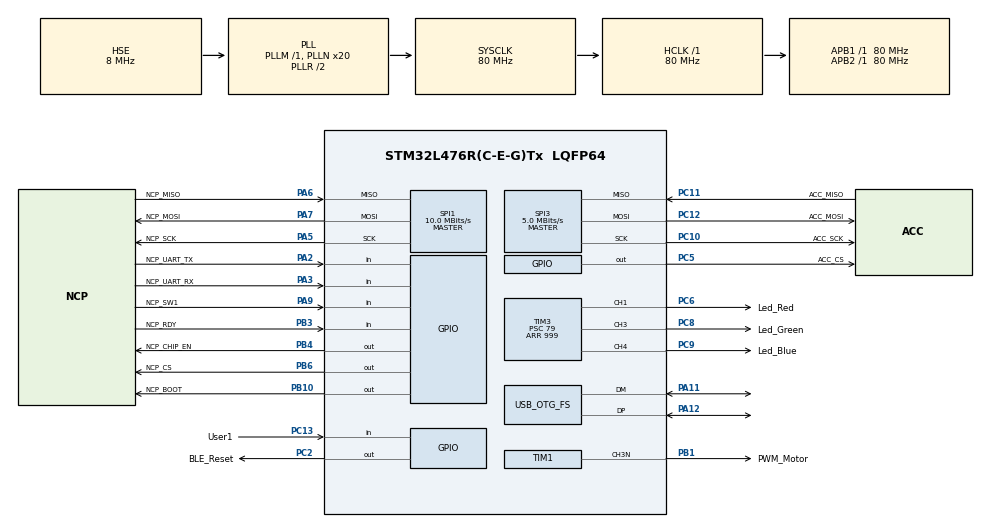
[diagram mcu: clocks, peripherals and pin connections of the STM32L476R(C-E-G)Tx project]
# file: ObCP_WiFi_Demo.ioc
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ADC1.Channel-0\#ChannelRegularConversion=ADC_CHANNEL_TEMPSENSOR
ADC1.ClockPrescaler=ADC_CLOCK_ASYNC_DIV4
ADC1.NbrOfConversionFlag=1
ADC1.OffsetNumber-0\#ChannelRegularConversion=ADC_OFFSET_NONE
ADC1.Rank-0\#ChannelRegularConversion=1
ADC1.SamplingTime-0\#ChannelRegularConversion=ADC_SAMPLETIME_640CYCLES_5
ADC1.master=1
Mcu.Family=STM32L4
Mcu.Name=STM32L476R(C-E-G)Tx
Mcu.Package=LQFP64
NVIC.OTG_FS_IRQn=true\:2\:0\:false\:false\:true\:false\:true\:true
NVIC.PriorityGroup=NVIC_PRIORITYGROUP_4
PA11.Mode=Device_Only
PA11.Signal=USB_OTG_FS_DM
PA12.Mode=Device_Only
PA12.Signal=USB_OTG_FS_DP
PA13\ (JTMS-SWDIO).GPIO_Label=TMS
PA13\ (JTMS-SWDIO).Mode=Serial_Wire
PA13\ (JTMS-SWDIO).Signal=SYS_JTMS-SWDIO
PA14\ (JTCK-SWCLK).GPIO_Label=TCK
PA14\ (JTCK-SWCLK).Mode=Serial_Wire
PA14\ (JTCK-SWCLK).Signal=SYS_JTCK-SWCLK
PA2.GPIO_Label=NCP_UART_TX
PA2.GPIO_PuPd=GPIO_PULLUP
PA2.Signal=GPIO_Input
PA3.GPIO_Label=NCP_UART_RX
PA3.GPIO_PuPd=GPIO_PULLUP
PA3.Signal=GPIO_Input
PA5.GPIO_Label=NCP_SCK
PA5.GPIO_PuPd=GPIO_PULLDOWN
PA5.Mode=Full_Duplex_Master
PA5.Signal=SPI1_SCK
PA6.GPIO_Label=NCP_MISO
PA6.Mode=Full_Duplex_Master
PA6.Signal=SPI1_MISO
PA7.GPIO_Label=NCP_MOSI
PA7.GPIO_PuPd=GPIO_PULLDOWN
PA7.Mode=Full_Duplex_Master
PA7.Signal=SPI1_MOSI
PA9.GPIO_Label=NCP_SW1
PA9.GPIO_PuPd=GPIO_PULLUP
PA9.Signal=GPIO_Input
PB1.GPIO_Label=PWM_Motor
PB1.Mode=PWM Generation3 CH3N
PB1.Signal=TIM1_CH3N
PB10.GPIO_Label=NCP_BOOT
PB10.Signal=GPIO_Output
PB3\ (JTDO-TRACESWO).GPIO_Label=NCP_RDY
PB3\ (JTDO-TRACESWO).GPIO_PuPd=GPIO_PULLDOWN
PB3\ (JTDO-TRACESWO).Signal=GPIO_Input
PB4\ (NJTRST).GPIO_Label=NCP_CHIP_EN
PB4\ (NJTRST).Signal=GPIO_Output
PB6.GPIO_Label=NCP_CS
PB6.GPIO_Speed=GPIO_SPEED_FREQ_HIGH
PB6.Signal=GPIO_Output
PC10.GPIO_Label=ACC_SCK
PC10.GPIO_PuPd=GPIO_PULLUP
PC10.GPIO_Speed=GPIO_SPEED_FREQ_HIGH
PC10.Mode=Full_Duplex_Master
PC10.Signal=SPI3_SCK
PC11.GPIO_Label=ACC_MISO
PC11.GPIO_PuPd=GPIO_PULLUP
PC11.GPIO_Speed=GPIO_SPEED_FREQ_HIGH
PC11.Mode=Full_Duplex_Master
PC11.Signal=SPI3_MISO
PC12.GPIO_Label=ACC_MOSI
PC12.GPIO_PuPd=GPIO_PULLUP
PC12.GPIO_Speed=GPIO_SPEED_FREQ_HIGH
PC12.Mode=Full_Duplex_Master
PC12.Signal=SPI3_MOSI
PC13.GPIO_Label=User1
PC13.GPIO_PuPd=GPIO_NOPULL
PC13.Signal=GPIO_Input
PC14-OSC32_IN\ (PC14).Mode=LSE-External-Oscillator
PC14-OSC32_IN\ (PC14).Signal=RCC_OSC32_IN
PC15-OSC32_OUT\ (PC15).Mode=LSE-External-Oscillator
PC15-OSC32_OUT\ (PC15).Signal=RCC_OSC32_OUT
PC2.GPIO_Label=BLE_Reset
PC2.Signal=GPIO_Output
PC5.GPIO_Label=ACC_CS
PC5.GPIO_Speed=GPIO_SPEED_FREQ_HIGH
PC5.PinState=GPIO_PIN_SET
PC5.Signal=GPIO_Output
PC6.GPIO_Label=Led_Red
PC6.Signal=S_TIM3_CH1
PC8.GPIO_Label=Led_Green
PC8.Signal=S_TIM3_CH3
PC9.GPIO_Label=Led_Blue
PC9.Signal=S_TIM3_CH4
PH0-OSC_IN\ (PH0).Mode=HSE-External-Oscillator
PH0-OSC_IN\ (PH0).Signal=RCC_OSC_IN
PH1-OSC_OUT\ (PH1).Mode=HSE-External-Oscillator
PH1-OSC_OUT\ (PH1).Signal=RCC_OSC_OUT
ProjectManager.HeapSize=0x400
ProjectManager.StackSize=0x1000
ProjectManager.TargetToolchain=STM32CubeIDE
RCC.ADCCLockSelection=RCC_ADCCLKSOURCE_SYSCLK
RCC.ADCFreq_Value=80000000
RCC.AHBFreq_Value=80000000
RCC.APB1Freq_Value=80000000
RCC.APB1TimFreq_Value=80000000
RCC.APB2Freq_Value=80000000
RCC.APB2TimFreq_Value=80000000
RCC.CortexFreq_Value=80000000
RCC.HCLKFreq_Value=80000000
RCC.HSE_VALUE=8000000
RCC.HSI_VALUE=16000000
RCC.LSE_Drive_Capability=RCC_LSEDRIVE_MEDIUMHIGH
RCC.MSI_VALUE=4000000
RCC.PLLN=20
RCC.PLLSAI1N=12
RCC.PLLSourceVirtual=RCC_PLLSOURCE_HSE
RCC.PREFETCH_ENABLE=1
RCC.RTCClockSelection=RCC_RTCCLKSOURCE_LSE
RCC.SYSCLKFreq_VALUE=80000000
RCC.SYSCLKSource=RCC_SYSCLKSOURCE_PLLCLK
RCC.USBFreq_Value=48000000
RCC.VCOOutputFreq_Value=160000000
SH.S_TIM3_CH1.0=TIM3_CH1,PWM Generation1 CH1
SH.S_TIM3_CH3.0=TIM3_CH3,PWM Generation3 CH3
SH.S_TIM3_CH4.0=TIM3_CH4,PWM Generation4 CH4
SPI1.BaudRatePrescaler=SPI_BAUDRATEPRESCALER_8
SPI1.CalculateBaudRate=10.0 MBits/s
SPI1.DataSize=SPI_DATASIZE_8BIT
SPI1.Direction=SPI_DIRECTION_2LINES
SPI1.Mode=SPI_MODE_MASTER
SPI1.NSSPMode=SPI_NSS_PULSE_DISABLE
SPI1.VirtualType=VM_MASTER
SPI3.BaudRatePrescaler=SPI_BAUDRATEPRESCALER_16
SPI3.CLKPhase=SPI_PHASE_2EDGE
SPI3.CLKPolarity=SPI_POLARITY_HIGH
SPI3.CalculateBaudRate=5.0 MBits/s
SPI3.DataSize=SPI_DATASIZE_8BIT
SPI3.Direction=SPI_DIRECTION_2LINES
SPI3.Mode=SPI_MODE_MASTER
SPI3.NSSPMode=SPI_NSS_PULSE_DISABLE
SPI3.VirtualType=VM_MASTER
TIM1.AutoReloadPreload=TIM_AUTORELOAD_PRELOAD_ENABLE
TIM1.Channel-PWM\ Generation3\ CH3N=TIM_CHANNEL_3
TIM1.Period=999
TIM1.Prescaler=79
TIM3.AutoReloadPreload=TIM_AUTORELOAD_PRELOAD_ENABLE
TIM3.Channel-PWM\ Generation1\ CH1=TIM_CHANNEL_1
TIM3.Channel-PWM\ Generation3\ CH3=TIM_CHANNEL_3
TIM3.Channel-PWM\ Generation4\ CH4=TIM_CHANNEL_4
TIM3.Period=999
TIM3.Prescaler=79
USB_DEVICE.CLASS_NAME_FS=CDC
USB_DEVICE.LANGID_STRING=1036
USB_DEVICE.MANUFACTURER_STRING=SUPMICROTECH-ENSMM
USB_DEVICE.PRODUCT_STRING_CDC_FS=ObCP WiFi 6 ST67W611M1
USB_DEVICE.VirtualMode=Cdc
USB_DEVICE.VirtualModeFS=Cdc_FS
USB_OTG_FS.VirtualMode=Device_Only
VP_ADC1_TempSens_Input.Mode=IN-TempSens
VP_ADC1_Vref_Input.Mode=IN-Vrefint
VP_RTC_VS_RTC_Activate.Mode=RTC_Enabled
VP_TIM1_VS_ClockSourceINT.Mode=Internal
VP_TIM3_VS_ClockSourceINT.Mode=Internal
VP_USB_DEVICE_VS_USB_DEVICE_CDC_FS.Mode=CDC_FS
board=custom

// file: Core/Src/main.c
/* USER CODE BEGIN Header */
/**
  ******************************************************************************
  * @file           : main.c
  * @brief          : Main program body
  ******************************************************************************
  * Démonstrateur Wi-Fi 6 : carte ObCP (STM32L476RG) + X-NUCLEO-67W61M1.
  *
  * Quatre démonstrations pilotées depuis un terminal série sur le port COM
  * virtuel USB de l'ObCP (prise micro-USB, aucun réglage de débit) :
  *   1. scanner Wi-Fi et suivi du RSSI (LED RVB)
  *   2. connexion et services réseau (DHCP / IP fixe, DNS, ping, SNTP -> RTC)
  *   3. serveur web en point d'accès (SoftAP)
  *   4. télémétrie MQTT (accéléromètre, LED RVB, sortie PWM)
  * Taper « help » dans le terminal pour la liste des commandes.
  *
  * Fichier généré par STM32CubeMX (ObCP_WiFi_Demo.ioc). Le code de la démo se
  * limite aux sections USER CODE (conservées à chaque régénération) :
  *   USER CODE 1     board_early_init() : saut éventuel dans le chargeur DFU ;
  *   USER CODE Init  board_lse_start()  : quartz 32 kHz (amplification) ;
  *   USER CODE 2     board_post_init(), app_init() ;
  *   USER CODE WHILE app_loop() dans la boucle principale ;
  *   Error_Handler   board_error_blink() : diagnostic par la LED rouge.
  * Le reste de la démo est dans des fichiers que CubeMX ne génère pas
  * (Core/Src/board.c, cdc_port.c, fault_handlers.c, uart_bridge.c,
  * ncp_port_obcp.c, Core/Src/app/, Core/Src/st67w6x/, Core/Src/qrcodegen/).
  *
  * Par où commencer la lecture ? Ce fichier (ordre du démarrage), puis
  * Core/Src/app/app.c (app_init, app_loop : le cœur de l'application),
  * cli.c (les commandes du terminal), une démo (demo_scan.c...), et enfin
  * le pilote du module (Core/Inc/ncp.h présente ses couches). Chaque
  * fonction est décrite dans l'en-tête .h qui la déclare ; carte du
  * programme et liste des fonctions : Doc/Documentation_Programme_ObCP.docx.
  ******************************************************************************
  * @attention
  *
  * Copyright (c) 2026 STMicroelectronics.
  * All rights reserved.
  *
  * This software is licensed under terms that can be found in the LICENSE file
  * in the root directory of this software component.
  * If no LICENSE file comes with this software, it is provided AS-IS.
  *
  ******************************************************************************
  */
/* USER CODE END Header */
#include "main.h"
#include "adc.h"
#include "rtc.h"
#include "spi.h"
#include "tim.h"
#include "usb_device.h"
#include "gpio.h"

/* USER CODE BEGIN Includes */
#include "board.h"
#include "app.h"
/* USER CODE END Includes */

void SystemClock_Config(void);

int main(void)
{

  /* USER CODE BEGIN 1 */
  board_early_init();            /* éventuel saut dans le chargeur USB DFU (commande « dfu ») */
  /* USER CODE END 1 */

  /* MCU Configuration--------------------------------------------------------*/

  /* Reset of all peripherals, Initializes the Flash interface and the Systick. */
  HAL_Init();

  /* USER CODE BEGIN Init */
  board_lse_start();             /* quartz 32 kHz avec l'amplification qu'il demande */
  /* USER CODE END Init */

  /* Configure the system clock */
  SystemClock_Config();

  /* Initialize all configured peripherals */
  MX_GPIO_Init();
  MX_SPI1_Init();
  MX_SPI3_Init();
  MX_ADC1_Init();
  MX_TIM1_Init();
  MX_TIM3_Init();
  MX_RTC_Init();
  MX_USB_DEVICE_Init();
  /* USER CODE BEGIN 2 */
  board_post_init();             /* SPI actifs, PWM démarrées, ADC étalonné, date de la RTC */
  app_init();                    /* configuration, module Wi-Fi, console */
  /* USER CODE END 2 */

  /* Infinite loop */
  /* USER CODE BEGIN WHILE */
  /* Boucle principale, sans fin : chaque tour lit le terminal et fait avancer
   * les tâches de fond (Wi-Fi, serveur web, MQTT). Aucune fonction ne doit y
   * rester bloquée longtemps : pas de RTOS, tout est « à tour de rôle ».   */
  while (1)
  {
    app_loop();
    /* USER CODE END WHILE */

  }
}

void SystemClock_Config(void)
{
  RCC_OscInitTypeDef RCC_OscInitStruct = {0};
  RCC_ClkInitTypeDef RCC_ClkInitStruct = {0};

  /** Configure the main internal regulator output voltage
  */
  if (HAL_PWREx_ControlVoltageScaling(PWR_REGULATOR_VOLTAGE_SCALE1) != HAL_OK)
  {
    Error_Handler();
  }

  /** Configure LSE Drive Capability
  */
  HAL_PWR_EnableBkUpAccess();
  __HAL_RCC_LSEDRIVE_CONFIG(RCC_LSEDRIVE_MEDIUMHIGH);

  /** Initializes the RCC Oscillators according to the specified parameters
  * in the RCC_OscInitTypeDef structure.
  */
  RCC_OscInitStruct.OscillatorType = RCC_OSCILLATORTYPE_HSE|RCC_OSCILLATORTYPE_LSE;
  RCC_OscInitStruct.HSEState = RCC_HSE_ON;
  RCC_OscInitStruct.LSEState = RCC_LSE_ON;
  RCC_OscInitStruct.PLL.PLLState = RCC_PLL_ON;
  RCC_OscInitStruct.PLL.PLLSource = RCC_PLLSOURCE_HSE;
  RCC_OscInitStruct.PLL.PLLM = 1;
  RCC_OscInitStruct.PLL.PLLN = 20;
  RCC_OscInitStruct.PLL.PLLP = RCC_PLLP_DIV7;
  RCC_OscInitStruct.PLL.PLLQ = RCC_PLLQ_DIV2;
  RCC_OscInitStruct.PLL.PLLR = RCC_PLLR_DIV2;
  if (HAL_RCC_OscConfig(&RCC_OscInitStruct) != HAL_OK)
  {
    Error_Handler();
  }

  /** Initializes the CPU, AHB and APB buses clocks
  */
  RCC_ClkInitStruct.ClockType = RCC_CLOCKTYPE_HCLK|RCC_CLOCKTYPE_SYSCLK
                              |RCC_CLOCKTYPE_PCLK1|RCC_CLOCKTYPE_PCLK2;
  RCC_ClkInitStruct.SYSCLKSource = RCC_SYSCLKSOURCE_PLLCLK;
  RCC_ClkInitStruct.AHBCLKDivider = RCC_SYSCLK_DIV1;
  RCC_ClkInitStruct.APB1CLKDivider = RCC_HCLK_DIV1;
  RCC_ClkInitStruct.APB2CLKDivider = RCC_HCLK_DIV1;

  if (HAL_RCC_ClockConfig(&RCC_ClkInitStruct, FLASH_LATENCY_4) != HAL_OK)
  {
    Error_Handler();
  }
}

void Error_Handler(void)
{
  /* USER CODE BEGIN Error_Handler_Debug */
  /* La console USB n'est pas forcément disponible : LED rouge clignotante
   * (2 éclats : quartz 8 MHz, 3 éclats : quartz 32 kHz, rapide : autre).  */
  board_error_blink();
  /* USER CODE END Error_Handler_Debug */
}
